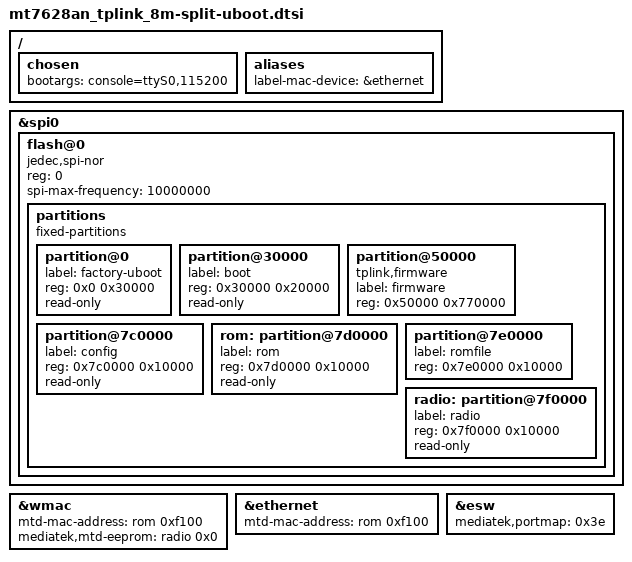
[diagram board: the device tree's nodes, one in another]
// SPDX-License-Identifier: GPL-2.0-or-later OR MIT

#include "mt7628an.dtsi"

#include <dt-bindings/gpio/gpio.h>
#include <dt-bindings/input/input.h>

/ {
	chosen {
		bootargs = "console=ttyS0,115200";
	};

	aliases {
		label-mac-device = &ethernet;
	};
};

&spi0 {
	status = "okay";

	flash@0 {
		compatible = "jedec,spi-nor";
		reg = <0>;
		spi-max-frequency = <10000000>;

		partitions {
			compatible = "fixed-partitions";
			#address-cells = <1>;
			#size-cells = <1>;

			partition@0 {
				label = "factory-uboot";
				reg = <0x0 0x30000>;
				read-only;
			};

			partition@30000 {
				label = "boot";
				reg = <0x30000 0x20000>;
				read-only;
			};

			partition@50000 {
				compatible = "tplink,firmware";
				label = "firmware";
				reg = <0x50000 0x770000>;
			};

			partition@7c0000 {
				label = "config";
				reg = <0x7c0000 0x10000>;
				read-only;
			};

			rom: partition@7d0000 {
				label = "rom";
				reg = <0x7d0000 0x10000>;
				read-only;
			};

			partition@7e0000 {
				label = "romfile";
				reg = <0x7e0000 0x10000>;
			};

			radio: partition@7f0000 {
				label = "radio";
				reg = <0x7f0000 0x10000>;
				read-only;
			};
		};
	};
};

&wmac {
	status = "okay";
	mtd-mac-address = <&rom 0xf100>;
	mediatek,mtd-eeprom = <&radio 0x0>;
};

&ethernet {
	mtd-mac-address = <&rom 0xf100>;
};

&esw {
	mediatek,portmap = <0x3e>;
};
